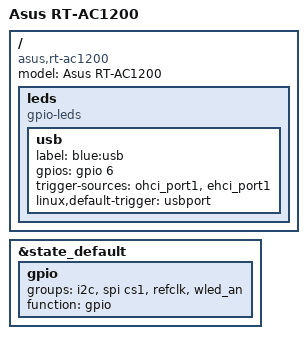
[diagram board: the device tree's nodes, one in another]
// SPDX-License-Identifier: GPL-2.0-or-later OR MIT
// Copyright (c) 2022 Ray Wang
// Copyright (c) 2022 Ivan Pavlov

#include "mt7628an_asus_rt-ac1200.dtsi"

/ {
	compatible = "asus,rt-ac1200", "mediatek,mt7628an-soc";
	model = "Asus RT-AC1200";

	leds {
		compatible = "gpio-leds";

		usb {
			label = "blue:usb";
			gpios = <&gpio 6 GPIO_ACTIVE_HIGH>;
			trigger-sources = <&ohci_port1>, <&ehci_port1>;
			linux,default-trigger = "usbport";
		};
	};
};

&state_default {
	gpio {
		groups = "i2c", "spi cs1", "refclk", "wled_an";
		function = "gpio";
	};
};
